# ATxmega32E5 device description
Architecture: AVR8_XMEGA; Family: AVR XMEGA
Registers are 8-bit, access not given, no defined reset value unless marked. A register's access mark holds for its fields unless they carry their own. Offsets are from the block's base; [hi:lo] are bit positions; {n}, {i} and the like mark numbered series; 'fields as' and 'values as' point back to an identical list.

## XCL — XMEGA Custom Logic
Instances: XCL 0x0460
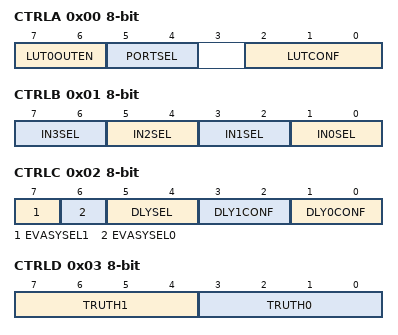
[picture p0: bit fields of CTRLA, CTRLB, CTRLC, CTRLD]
0x00 CTRLA — Control Register A
  [7:6] LUT0OUTEN — LUT0 Output Enable
    0=DISABLE (LUT0 output disabled); 1=PIN0 (LUT0 Output to pin 0); 2=PIN4 (LUT0 Output to pin 4)
  [5:4] PORTSEL — Port Selection
    0=PC (Port C for LUT or USARTC0 for PEC); 1=PD (Port D for LUT or USARTD0 for PEC)
  [2:0] LUTCONF — LUT Configuration
    0=2LUT2IN (2-Input two LUT); 1=2LUT1IN (Two LUT with duplicated input); 2=2LUT3IN (Two LUT with one common input); 3=1LUT3IN (3-Input LUT); 4=MUX (One LUT Mux); 5=DLATCH (One D-Latch LUT); 6=RSLATCH (One RS-Latch LUT); 7=DFF (One DFF LUT)
0x01 CTRLB — Control Register B
  [all] fields
    0=EVSYS (Event system selected as source); 1=XCL (XCL selected as source); 2=PINL (LSB port pin selected as source); 3=PINH (MSB port pin selected as source)
  [2n+1:2n] IN{n}SEL (n=0..3) — Input Selection {n}
0x02 CTRLC — Control Register C
  [7] EVASYSEL1 — Asynchronous Event Line Selection for LUT1
  [6] EVASYSEL0 — Asynchronous Event Line Selection for LUT0
  [5:4] DLYSEL — Delay Selection
    0=DLY11 (One cycle delay for each LUT1 and LUT0); 1=DLY12 (One cycle delay for LUT1 and two cycles for LUT0); 2=DLY21 (Two cycles delay for LUT1 and one cycle for LUT0); 3=DLY22 (Two cycle delays for each LUT1 and LUT0)
  [3:2] DLY1CONF — Delay Configuration on LUT1
    0=DISABLE (Delay element disabled); 1=IN (Delay enabled on LUT input); 2=OUT (Delay enabled on LUT output)
  [1:0] DLY0CONF — Delay Configuration on LUT0
    values as DLY1CONF
0x03 CTRLD — Control Register D
  [7:4] TRUTH1 — Truth Table of LUT1
  [3:0] TRUTH0 — Truth Table of LUT0
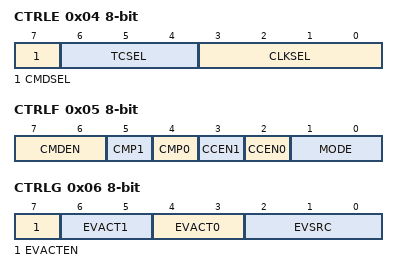
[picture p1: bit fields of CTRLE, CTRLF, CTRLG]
0x04 CTRLE — Control Register E
  [7] CMDSEL — Timer/Counter Command Selection
    0=NONE; 1=RESTART (Force restart)
  [6:4] TCSEL — Timer/Counter Selection
    0=TC16 (16-bit timer/counter); 1=BTC0 (One 8-bit timer/counter); 2=BTC01 (Two 8-bit timer/counters); 3=BTC0PEC1 (One 8-bit timer/counter and one 8-bit peripheral transmitter counter); 4=PEC0BTC1 (One 8-bit timer/counter and one 8-bit peripheral receiver counter); 5=PEC01 (Two 8-bit peripheral counters); 6=BTC0PEC2 (One 8-bit timer/counter and two 4-bit peripheral counters)
  [3:0] CLKSEL — Clock Selection
    0=OFF; 1=DIV1 (Prescaler clk); 2=DIV2 (Prescaler clk/2); 3=DIV4 (Prescaler clk/4); 4=DIV8 (Prescaler clk/8); 5=DIV64 (Prescaler clk/64); 6=DIV256 (Prescaler clk/256); 7=DIV1024 (Prescaler clk/1024); {v}=EVCH{v-8} (Event channel {v-8}) (v=8..15)
0x05 CTRLF — Control Register F
  [7:6] CMDEN — Command Enable
    0=DISABLE (Command Ignored); 1=CMD0 (Command valid for timer/counter 0); 2=CMD1 (Command valid for timer/counter 1); 3=CMD01 (Command valid for both timer/counter 0 and 1)
  [5] CMP1 — Compare Channel 1 Output Value
    0=CLEAR (Clear WG Output); 1=SET (Set WG Output)
  [4] CMP0 — Compare Channel 0 Output Value
    0=CLEAR (Clear WG Output); 1=SET (Set WG Output)
  [3] CCEN1 — Compare or Capture Channel 1 Enable
  [2] CCEN0 — Compare or Capture Channel 0 Enable
  [1:0] MODE — Timer/Counter Mode
    0=NORMAL (Normal mode with compare/period); 1=CAPT (Capture mode); 2=PWM (Single Slope PWM); 3=1SHOT (One-shot PWM)
0x06 CTRLG — Control Register G
  [7] EVACTEN — Event Action Enable
  [6:5] EVACT1 — Event Action Selection on Timer/Counter 1
    0=INPUT (Input Capture); 1=FREQ (Frequency Capture); 2=PW (Pulse Width Capture); 3=RESTART (Restart timer/counter)
  [4:3] EVACT0 — Event Action Selection on Timer/Counter 0
    values as EVACT1
  [2:0] EVSRC — Event Source Selection
    {v}=EVCH{v} (Event channel {v}) (v=0..7)
0x07 INTCTRL — Interrupt Control Register
  [7] UNF1IE — Underflow 1 Interrupt Enable
  [7] PEC1IE — Peripheral Counter 1 Interrupt Enable
  [7] PEC21IE — Peripheral High Counter 2 Interrupt Enable
  [6] UNF0IE — Underflow 0 Interrupt Enable
  [6] PEC0IE — Peripheral Counter 0 Interrupt Enable
  [5] CC1IE — Compare Or Capture 1 Interrupt Enable
  [5] PEC20IE — Peripheral Low Counter 2 Interrupt Enable
  [4] CC0IE — Compare Or Capture 0 Interrupt Enable
  [3:2] UNFINTLVL — Timer Underflow Interrupt Level
    0=OFF (Interrupt Disabled); 1=LO (Low Level); 2=MED (Medium Level); 3=HI (High Level)
  [1:0] CCINTLVL — Timer Compare or Capture Interrupt Level
    values as UNFINTLVL
0x08 INTFLAGS — Interrupt Flag Register
  [7] UNF1IF — Timer/Counter 1 Underflow Interrupt Flag
  [7] PEC1IF — Peripheral Counter 1 Interrupt Flag
  [7] PEC21IF — Peripheral High Counter 2 Interrupt Flag
  [6] UNF0IF — Timer/Counter 0 Underflow Interrupt Flag
  [6] PEC0IF — Peripheral Counter 0 Interrupt Flag
  [5] CC1IF — Compare or Capture Channel 1 Interrupt Flag
  [5] PEC20IF — Peripheral Low Counter 2 Interrupt Flag
  [4] CC0IF — Compare or Capture Channel 0 Interrupt Flag
0x09 PLC — Peripheral Lenght Control Register
  [7:0] PLC — Peripheral Lenght Control Bits
0x0A CNTL — Counter Register Low
  [7:0] BCNTO — BTC0 Counter Byte
  [7:0] CNTL — TC16 Counter Low Byte
  [7:0] PCNTO — Peripheral Counter 0 Byte
0x0B CNTH — Counter Register High
  [7:4] PCNT21 — Peripheral High Counter 2 Bits
  [7:0] BCNT1 — BTC1 Counter Byte
  [7:0] CNTH — TC16 Counter High Byte
  [7:0] PCNT1 — Peripheral Counter 1 Byte
  [3:0] PCNT20 — Peripheral Low Counter 2 Bits
0x0C CMPL — Compare Register Low
  [7:0] CMPL — TC16 Compare Low Byte
  [7:0] BCMP0 — BTC0 Compare Byte
0x0D CMPH — Compare Register High
  [7:0] CMPH — TC16 Compare High Byte
  [7:0] BCMP1 — BTC1 Compare Byte
0x0E PERCAPTL — Period or Capture Register Low
  [7:0] PERL — TC16 Low Byte Period
  [7:0] CAPTL — TC16 Capture Value Low Byte
  [7:0] BPER0 — BTC0 Period
  [7:0] BCAPT0 — BTC0 Capture Value Byte
0x0F PERCAPTH — Period or Capture Register High
  [7:0] PERH — TC16 High Byte Period
  [7:0] CAPTH — TC16 Capture Value High Byte
  [7:0] BPER1 — BTC1 Period
  [7:0] BCAPT1 — BTC1 Capture Value Byte
